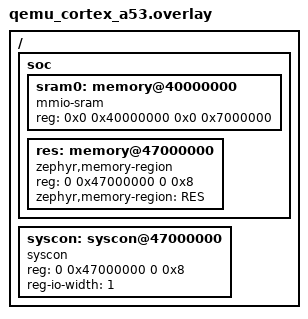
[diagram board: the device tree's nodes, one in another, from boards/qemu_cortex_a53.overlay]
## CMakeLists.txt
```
# Copyright 2021 Google LLC
# SPDX-License-Identifier: Apache-2.0

cmake_minimum_required(VERSION 3.20.0)

find_package(Zephyr REQUIRED HINTS $ENV{ZEPHYR_BASE})
project(syscon)

FILE(GLOB app_sources src/*.c)
target_sources(app PRIVATE ${app_sources})
```

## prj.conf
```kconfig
# Copyright 2021 Google LLC
# SPDX-License-Identifier: Apache-2.0

CONFIG_ZTEST=y
CONFIG_SYSCON=y
CONFIG_MMU=y
CONFIG_HAVE_CUSTOM_LINKER_SCRIPT=y
CONFIG_CUSTOM_LINKER_SCRIPT="linker_arm64_reserved.ld"
```

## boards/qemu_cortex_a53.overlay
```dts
/* Copyright 2021 Google LLC
 * SPDX-License-Identifier: Apache-2.0
 */

/ {
	soc {
		sram0: memory@40000000 {
			compatible = "mmio-sram";
			reg = < 0x0 0x40000000 0x0 0x7000000 >;
		};

		res: memory@47000000 {
			compatible = "zephyr,memory-region", "mmio-sram";
			reg = <0 0x47000000 0 0x8>;
			zephyr,memory-region = "RES";
		};
	};

	syscon: syscon@47000000 {
		compatible = "syscon";
		status = "okay";
		reg = <0 0x47000000 0 0x8>;
		reg-io-width = <1>;
	};
};
```

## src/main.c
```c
/* Copyright 2021 Google LLC
 * SPDX-License-Identifier: Apache-2.0
 */

#include <zephyr/device.h>
#include <zephyr/devicetree.h>
#include <zephyr/drivers/syscon.h>
#include <zephyr/ztest.h>
#include <zephyr/linker/devicetree_regions.h>

#define RES_SECT LINKER_DT_NODE_REGION_NAME(DT_NODELABEL(res))

uint8_t var_in_res0[DT_REG_SIZE(DT_NODELABEL(syscon))] __attribute((__section__(RES_SECT)));

ZTEST(syscon, test_size)
{
	const struct device *const dev = DEVICE_DT_GET(DT_NODELABEL(syscon));
	const size_t expected_size = DT_REG_SIZE(DT_NODELABEL(syscon));
	size_t size;

	zassert_not_null(dev, NULL);
	zassert_ok(syscon_get_size(dev, &size));
	zassert_equal(size, expected_size, "size(0x%x) != expected_size(0x%x)", size,
		      expected_size);
}

ZTEST(syscon, test_out_of_bounds)
{
	const struct device *const dev = DEVICE_DT_GET(DT_NODELABEL(syscon));
	uint32_t val;

	zassert_equal(syscon_read_reg(dev, DT_REG_SIZE(DT_NODELABEL(syscon)), &val), -EINVAL);
	zassert_equal(syscon_write_reg(dev, DT_REG_SIZE(DT_NODELABEL(syscon)), val), -EINVAL);
}

ZTEST(syscon, test_read)
{
	const struct device *const dev = DEVICE_DT_GET(DT_NODELABEL(syscon));
	uintptr_t base_addr;
	uint32_t val;

	zassert_ok(syscon_get_base(dev, &base_addr));
	for (size_t i = 0; i < ARRAY_SIZE(var_in_res0); ++i) {
		((uint8_t *)base_addr)[i] = i;
		zassert_ok(syscon_read_reg(dev, i, &val));
		zassert_equal(i, val);
	}
}

ZTEST(syscon, test_write)
{
	const struct device *const dev = DEVICE_DT_GET(DT_NODELABEL(syscon));
	uintptr_t base_addr;

	zassert_ok(syscon_get_base(dev, &base_addr));
	for (uint32_t i = 0; i < ARRAY_SIZE(var_in_res0); ++i) {
		zassert_ok(syscon_write_reg(dev, i, i));
		zassert_equal(((uint8_t *)base_addr)[i], i);
	}
}

ZTEST_SUITE(syscon, NULL, NULL, NULL, NULL, NULL);
```
